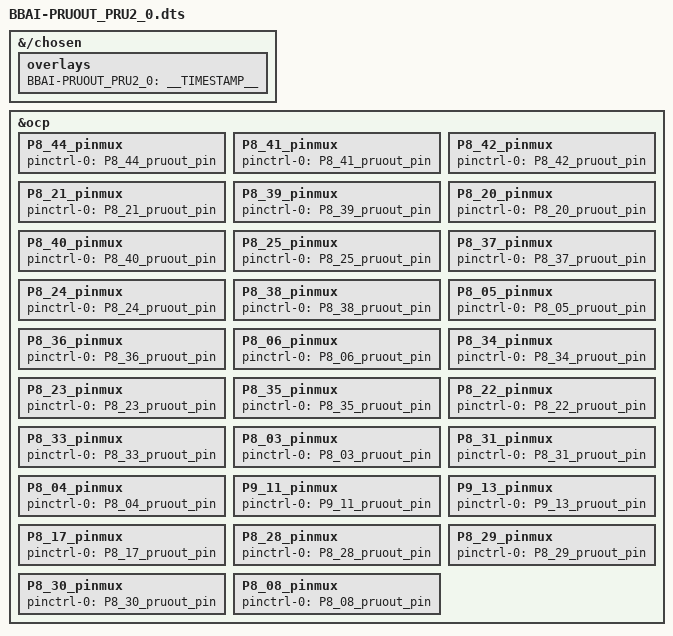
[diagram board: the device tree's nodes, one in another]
/*
 * Copyright (C) 2020 Deepak Khatri <deepaklorkhatri7@gmail.com>
 * See Cape Interface Spec page for more info on Bone Buses
 * https://elinux.org/Beagleboard:BeagleBone_cape_interface_spec
 *
 * Virtual cape for pr2_pru0_gpo* pins
 *
 * This program is free software; you can redistribute it and/or modify
 * it under the terms of the GNU General Public License version 2 as
 * published by the Free Software Foundation.
 */
/dts-v1/;
/plugin/;

/*
* Helper to show loaded overlays under: /proc/device-tree/chosen/overlays/
*/
&{/chosen} {
    overlays {
        BBAI-PRUOUT_PRU2_0 = __TIMESTAMP__;
    };
};

/*
 * Update the default pinmux of the pins.
 * See these files for the phandles (&P9_* & &P8_*)
 * BeagleBoard-DeviceTrees/v4.19.x-ti-overlays/src/arm/am335x-bone-common-univ.dtsi
 * BeagleBoard-DeviceTrees/v4.19.x-ti-overlays/src/arm/am572x-bone-common-univ.dtsi
 */
&ocp {
    P8_44_pinmux { pinctrl-0 = <&P8_44_pruout_pin>; }; /* pr2_pru0_gpo0 */
	P8_41_pinmux { pinctrl-0 = <&P8_41_pruout_pin>; }; /* pr2_pru0_gpo1 */

	P8_42_pinmux { pinctrl-0 = <&P8_42_pruout_pin>; }; /* pr2_pru0_gpo2 */
	P8_21_pinmux { pinctrl-0 = <&P8_21_pruout_pin>; }; /* pr2_pru0_gpo2 */

	P8_39_pinmux { pinctrl-0 = <&P8_39_pruout_pin>; }; /* pr2_pru0_gpo3 */
	P8_20_pinmux { pinctrl-0 = <&P8_20_pruout_pin>; }; /* pr2_pru0_gpo3 */

	P8_40_pinmux { pinctrl-0 = <&P8_40_pruout_pin>; }; /* pr2_pru0_gpo4 */
	P8_25_pinmux { pinctrl-0 = <&P8_25_pruout_pin>; }; /* pr2_pru0_gpo4 */

	P8_37_pinmux { pinctrl-0 = <&P8_37_pruout_pin>; }; /* pr2_pru0_gpo5 */
	P8_24_pinmux { pinctrl-0 = <&P8_24_pruout_pin>; }; /* pr2_pru0_gpo5 */

	P8_38_pinmux { pinctrl-0 = <&P8_38_pruout_pin>; }; /* pr2_pru0_gpo6 */
	P8_05_pinmux { pinctrl-0 = <&P8_05_pruout_pin>; }; /* pr2_pru0_gpo6 */

	P8_36_pinmux { pinctrl-0 = <&P8_36_pruout_pin>; }; /* pr2_pru0_gpo7 */
	P8_06_pinmux { pinctrl-0 = <&P8_06_pruout_pin>; }; /* pr2_pru0_gpo7 */

	P8_34_pinmux { pinctrl-0 = <&P8_34_pruout_pin>; }; /* pr2_pru0_gpo8 */
	P8_23_pinmux { pinctrl-0 = <&P8_23_pruout_pin>; }; /* pr2_pru0_gpo8 */

	P8_35_pinmux { pinctrl-0 = <&P8_35_pruout_pin>; }; /* pr2_pru0_gpo9 */
	P8_22_pinmux { pinctrl-0 = <&P8_22_pruout_pin>; }; /* pr2_pru0_gpo9 */

	P8_33_pinmux { pinctrl-0 = <&P8_33_pruout_pin>; }; /* pr2_pru0_gpo10 */
	P8_03_pinmux { pinctrl-0 = <&P8_03_pruout_pin>; }; /* pr2_pru0_gpo10 */

	P8_31_pinmux { pinctrl-0 = <&P8_31_pruout_pin>; }; /* pr2_pru0_gpo11 */
	P8_04_pinmux { pinctrl-0 = <&P8_04_pruout_pin>; }; /* pr2_pru0_gpo11 */


    P9_11_pinmux { pinctrl-0 = <&P9_11_pruout_pin>; }; /* pr2_pru0_gpo */

	P9_13_pinmux { pinctrl-0 = <&P9_13_pruout_pin>; }; /* pr2_pru0_gpo */
	P8_17_pinmux { pinctrl-0 = <&P8_17_pruout_pin>; }; /* pr2_pru0_gpo */

	P8_28_pinmux { pinctrl-0 = <&P8_28_pruout_pin>; }; /* pr2_pru0_gpo */
	P8_29_pinmux { pinctrl-0 = <&P8_29_pruout_pin>; }; /* pr2_pru0_gpo */
	P8_30_pinmux { pinctrl-0 = <&P8_30_pruout_pin>; }; /* pr2_pru0_gpo */
	P8_08_pinmux { pinctrl-0 = <&P8_08_pruout_pin>; }; /* pr2_pru0_gpo */
};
